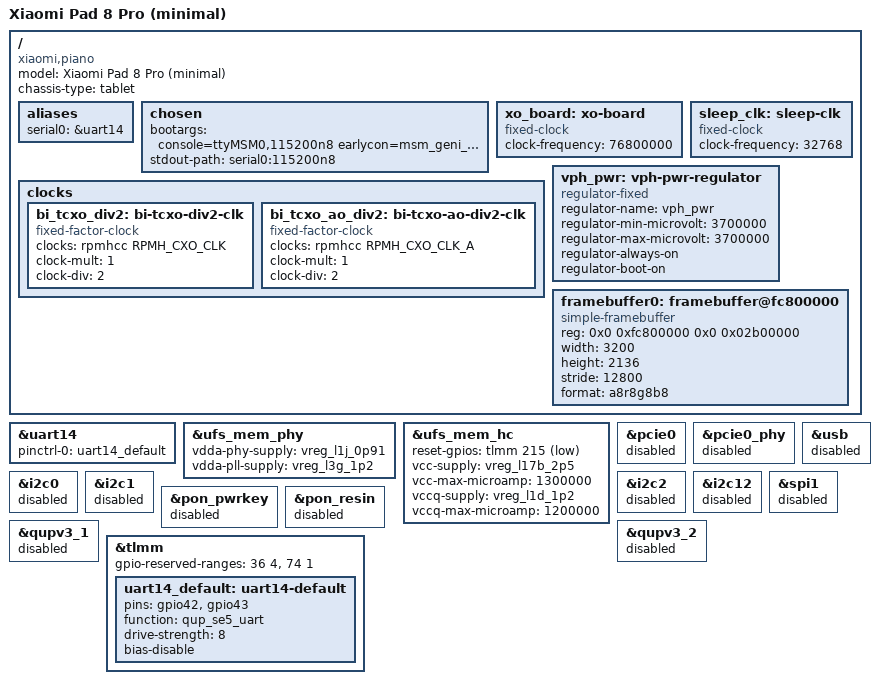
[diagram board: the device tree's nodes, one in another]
// SPDX-License-Identifier: (GPL-2.0+ OR MIT)
/*
 * Minimal device tree for Xiaomi Pad 8 Pro (SM8750-AB)
 *
 * 目标：编译通过 + 串口有输出 + UFS 能挂载
 * 策略：只保留最小子系统，其余全部 disabled 或删除
 *
 * 验证清单：
 *   [ ] make dtbs 无报错
 *   [ ] 串口 115200 有 earlycon 输出
 *   [ ] UFS 枚举成功，/dev/block/by-name/userdata 存在
 *   [ ] simplefb 帧缓冲地址与 XBL 一致（需确认）
 *
 * 待确认项（标记 TODO）：
 *   - GPIO 42/43 的 QUP SE function 名称
 *   - 帧缓冲地址 0xfc800000
 *   - gpio-reserved-ranges
 *   - UFS reset GPIO 编号
 */

/dts-v1/;

#include <dt-bindings/gpio/gpio.h>
#include <dt-bindings/clock/qcom,rpmh.h>
#include "sm8750.dtsi"
#include "pm8010.dtsi"
#include "pm8550.dtsi"
#define PMK8550VE_SID 8
#include "pm8550ve.dtsi"
#include "pmd8028.dtsi"
#include "pmih0108.dtsi"
#include "pmk8550.dtsi"
#include "pmr735d_a.dtsi"
#include "sm8750-pmics.dtsi"

/ {
	model = "Xiaomi Pad 8 Pro (minimal)";
	compatible = "xiaomi,piano", "qcom,sm8750-piano", "qcom,sm8750";
	chassis-type = "tablet";

	aliases {
		serial0 = &uart14;
	};

	chosen {
		/*
		 * WARNING: root=/dev/block/by-name/userdata 会擦除安卓数据！
		 * 调试阶段建议先用 init=/bin/sh 避免挂载根文件系统。
		 */
		bootargs = "console=ttyMSM0,115200n8 earlycon=msm_geni_serial,0xa9c000 init=/bin/sh loglevel=7";
		stdout-path = "serial0:115200n8";
	};

	/* ── 时钟（sm8750.dtsi 引用但未定义，板级必须提供）── */

	xo_board: xo-board {
		compatible = "fixed-clock";
		#clock-cells = <0>;
		clock-frequency = <76800000>;
	};

	sleep_clk: sleep-clk {
		compatible = "fixed-clock";
		#clock-cells = <0>;
		clock-frequency = <32768>;
	};

	clocks {
		bi_tcxo_div2: bi-tcxo-div2-clk {
			compatible = "fixed-factor-clock";
			#clock-cells = <0>;
			clocks = <&rpmhcc RPMH_CXO_CLK>;
			clock-mult = <1>;
			clock-div = <2>;
		};

		bi_tcxo_ao_div2: bi-tcxo-ao-div2-clk {
			compatible = "fixed-factor-clock";
			#clock-cells = <0>;
			clocks = <&rpmhcc RPMH_CXO_CLK_A>;
			clock-mult = <1>;
			clock-div = <2>;
		};
	};

	/* ── VPH 电源（高通平台基础电源轨）── */

	vph_pwr: vph-pwr-regulator {
		compatible = "regulator-fixed";
		regulator-name = "vph_pwr";
		regulator-min-microvolt = <3700000>;
		regulator-max-microvolt = <3700000>;
		regulator-always-on;
		regulator-boot-on;
	};

	/* ── 简单帧缓冲 ──────────────────────────────────────
	 * TODO: 地址 0xfc800000 需与 XBL/ABL 预留地址一致。
	 * 确认方法：从原厂 boot.img cmdline 提取 fb_addr，
	 * 或串口看 XBL 输出 "Framebuffer at 0x..." 。
	 * 若地址不对，删除此节点，改用 DRM panic console。
	 */

	framebuffer0: framebuffer@fc800000 {
		compatible = "simple-framebuffer";
		reg = <0x0 0xfc800000 0x0 0x02b00000>;
		width = <3200>;
		height = <2136>;
		stride = <12800>;
		format = "a8r8g8b8";
		status = "okay";
	};
};

/* ═══════════════════════════════════════════════════════════
 *  调试串口 — ttyMSM0 @ 0xa9c000 (UART14, GPIO 42/43)
 *
 *  TODO: function 名称 "qup_se5_uart" 仅为推测，
 *  需对照 SM8750 TRM 确认 GPIO 42/43 对应的 QUP SE 编号。
 *  如果串口无输出，尝试改为 qup_se0_uart ~ qup_se15_uart 逐个测试。
 * ═══════════════════════════════════════════════════════════ */

&uart14 {
	status = "okay";
	pinctrl-names = "default";
	pinctrl-0 = <&uart14_default>;
};

/* ═══════════════════════════════════════════════════════════
 *  UFS 存储 — ufshc @ 0x1d84000
 *
 *  供电引用来自 PMIC dtsi。若编译报 undefined label，
 *  需包含对应的 PMIC 头文件或删除供电属性。
 * ═══════════════════════════════════════════════════════════ */

&ufs_mem_phy {
	/* 供电引用来自 PMIC dtsi，与 MTP 一致 */
	vdda-phy-supply = <&vreg_l1j_0p91>;
	vdda-pll-supply = <&vreg_l3g_1p2>;
	status = "okay";
};

&ufs_mem_hc {
	/* TODO: reset GPIO 编号 215 需确认 */
	reset-gpios = <&tlmm 215 GPIO_ACTIVE_LOW>;
	vcc-supply = <&vreg_l17b_2p5>;
	vcc-max-microamp = <1300000>;
	vccq-supply = <&vreg_l1d_1p2>;
	vccq-max-microamp = <1200000>;
	status = "okay";
};

/* ═══════════════════════════════════════════════════════════
 *  以下节点全部 disabled，仅在验证通过后逐个启用
 * ═══════════════════════════════════════════════════════════ */

/* PCIe — WiFi (WCN7850) */
&pcie0 {
	status = "disabled";
};
&pcie0_phy {
	status = "disabled";
};

/* USB */
&usb {
	status = "disabled";
};

/* I2C / SPI / 其他外设 — 全部 disabled */
&i2c0 { status = "disabled"; };
&i2c1 { status = "disabled"; };
&i2c2 { status = "disabled"; };
&i2c12 { status = "disabled"; };
&spi1 { status = "disabled"; };

/* PMIC 功能 */
&pon_pwrkey { status = "disabled"; };
&pon_resin { status = "disabled"; };

/* QUP */
&qupv3_1 { status = "disabled"; };
&qupv3_2 { status = "disabled"; };

/* ═══════════════════════════════════════════════════════════
 *  Pinmux — 最小集，仅保留串口
 * ═══════════════════════════════════════════════════════════ */

&tlmm {
	/* TODO: 需确认和平板 XBL 实际保留一致 */
	gpio-reserved-ranges = <36 4>, <74 1>;

	uart14_default: uart14-default {
		pins = "gpio42", "gpio43";
		/* TODO: function 名称需确认，错误会导致串口无输出 */
		function = "qup_se5_uart";
		drive-strength = <8>;
		bias-disable;
	};
};
